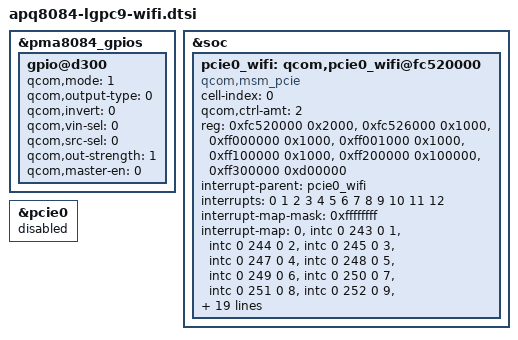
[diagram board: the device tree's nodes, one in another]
/* Copyright (c) 2012, Code Aurora Forum. All rights reserved.
 *
 * This program is free software; you can redistribute it and/or modify
* it under the terms of the GNU General Public License version 2 and
* only version 2 as published by the Free Software Foundation.
*
* This program is distributed in the hope that it will be useful,
* but WITHOUT ANY WARRANTY; without even the implied warranty of
* MERCHANTABILITY or FITNESS FOR A PARTICULAR PURPOSE.  See the
* GNU General Public License for more details.
*/


/*  LGE_CHANGE_S, [WiFi][moon_wifi@lge.com], Setting for WiFi by jw*/
&pma8084_gpios {
	gpio@d300 { /* GPIO 20 */
		status = "ok";           /* WIFI_SLEEP_CLK */
		qcom,mode = <1>;         /* Digital output */
		qcom,output-type = <0>;  /* CMOS logic */
		qcom,invert = <0>;       /* Do not invert the output */
		qcom,vin-sel = <0>;      /* VPH_PWR */
		qcom,src-sel = <0>;      /* GPIO */
		qcom,out-strength = <1>; /* High drive strength */
		qcom,master-en = <0>;    /* Enable GPIO */
	};
};

&soc {
	pcie0_wifi: qcom,pcie0_wifi@fc520000 {
		compatible = "qcom,msm_pcie";
		cell-index = <0>;
		qcom,ctrl-amt = <2>;

		reg = <0xfc520000 0x2000>,
		      <0xfc526000 0x1000>,
		      <0xff000000 0x1000>,
		      <0xff001000 0x1000>,
		      <0xff100000 0x1000>,
		      <0xff200000 0x100000>,
		      <0xff300000 0xd00000>;

		reg-names = "parf", "phy", "dm_core", "elbi",
				"conf", "io", "bars";

		#address-cells = <0>;
		interrupt-parent = <&pcie0_wifi>;
		interrupts = <0 1 2 3 4 5 6 7 8 9 10 11 12>;
		#interrupt-cells = <1>;
		interrupt-map-mask = <0xffffffff>;
		interrupt-map = <0 &intc 0 243 0
				1 &intc 0 244 0
				2 &intc 0 245 0
				3 &intc 0 247 0
				4 &intc 0 248 0
				5 &intc 0 249 0
				6 &intc 0 250 0
				7 &intc 0 251 0
				8 &intc 0 252 0
				9 &intc 0 253 0
				10 &intc 0 254 0
				11 &intc 0 255 0
				12 &msmgpio 69 0x2>;   /*OOB or PME */
		interrupt-names = "int_msi", "int_a", "int_b", "int_c", "int_d",
				"int_pls_pme", "int_pme_legacy", "int_pls_err",
				"int_aer_legacy", "int_pls_link_up",
				"int_pls_link_down", "int_bridge_flush_n",
				"int_wake";

		perst-gpio = <&msmgpio 70 0>;
		wake-gpio = <&msmgpio 69 0>;   /*OOB or PME */
		clkreq-gpio = <&msmgpio 68 0>;

		gdsc-vdd-supply = <&gdsc_pcie_0>;
		vreg-1.8-supply = <&pma8084_l12>;
		vreg-0.9-supply = <&pma8084_l3>;

		qcom,l1ss-supported;
		qcom,n-fts = <0x50>;
		qcom,ep-latency = <10>;

		qcom,msi-gicm-addr = <0xf9040040>;
		qcom,msi-gicm-base = <0x160>;

		qcom,msm-bus,name = "pcie0";
		qcom,msm-bus,num-cases = <2>;
		qcom,msm-bus,num-paths = <1>;
		qcom,msm-bus,vectors-KBps =
				<45 512 0 0>,
				<45 512 500 800>;
		qcom,ep-wakeirq;      /*Don't pcie enumerate when pcie probe. Will be enumerated upon WAKE_N IRQ from BCM4356 */
	};
};

&pcie0{
	status = "disable";
};
/*  LGE_CHANGE_E, [WiFi][moon_wifi@lge.com], Setting for WiFi by jw*/

